VERSION ""

NS_ :

BS_:

BU_: GENERIC_SENSOR_HUB

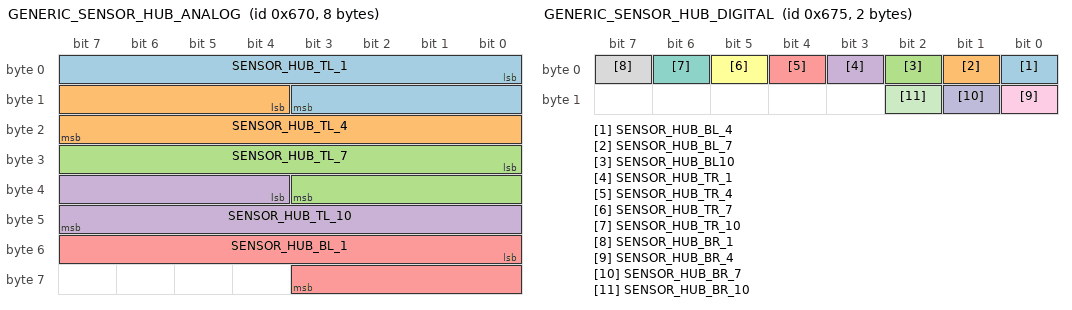
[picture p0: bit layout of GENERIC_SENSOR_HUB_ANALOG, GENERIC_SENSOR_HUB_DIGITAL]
BO_ 1648 GENERIC_SENSOR_HUB_ANALOG: 8 GENERIC_SENSOR_HUB
 SG_ SENSOR_HUB_TL_1 : 0|12@1+ (0.0008056640625,0) [0|3.3] "V" Vector__XXX
 SG_ SENSOR_HUB_TL_4 : 12|12@1+ (0.0008056640625,0) [0|3.3] "V" Vector__XXX
 SG_ SENSOR_HUB_TL_7 : 24|12@1+ (0.0008056640625,0) [0|3.3] "V" Vector__XXX
 SG_ SENSOR_HUB_TL_10 : 36|12@1+ (0.0008056640625,0) [0|3.3] "V" Vector__XXX
 SG_ SENSOR_HUB_BL_1 : 48|12@1+ (0.0008056640625,0) [0|3.3] "V" Vector__XXX

BO_ 1653 GENERIC_SENSOR_HUB_DIGITAL: 2 GENERIC_SENSOR_HUB
 SG_ SENSOR_HUB_BL_4 : 0|1@1+ (1,0) [0|1] "" Vector__XXX
 SG_ SENSOR_HUB_BL_7 : 1|1@1+ (1,0) [0|1] "" Vector__XXX
 SG_ SENSOR_HUB_BL10 : 2|1@1+ (1,0) [0|1] "" Vector__XXX
 SG_ SENSOR_HUB_TR_1 : 3|1@1+ (1,0) [0|1] "" Vector__XXX
 SG_ SENSOR_HUB_TR_4 : 4|1@1+ (1,0) [0|1] "" Vector__XXX
 SG_ SENSOR_HUB_TR_7 : 5|1@1+ (1,0) [0|1] "" Vector__XXX
 SG_ SENSOR_HUB_TR_10 : 6|1@1+ (1,0) [0|1] "" Vector__XXX
 SG_ SENSOR_HUB_BR_1 : 7|1@1+ (1,0) [0|1] "" Vector__XXX
 SG_ SENSOR_HUB_BR_4 : 8|1@1+ (1,0) [0|1] "" Vector__XXX
 SG_ SENSOR_HUB_BR_7 : 9|1@1+ (1,0) [0|1] "" Vector__XXX
 SG_ SENSOR_HUB_BR_10 : 10|1@1+ (1,0) [0|1] "" Vector__XXX

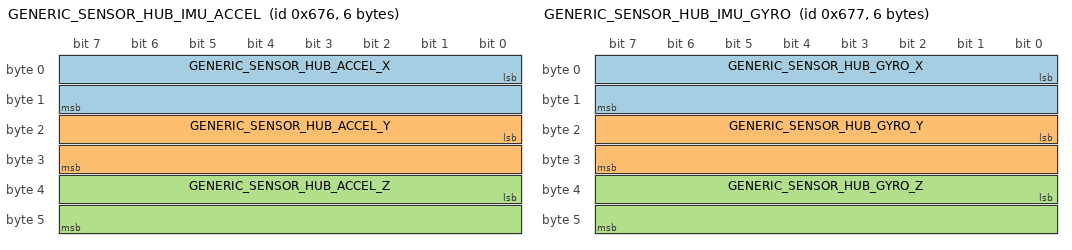
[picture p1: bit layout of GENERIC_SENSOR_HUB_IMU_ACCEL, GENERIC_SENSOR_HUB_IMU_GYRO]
BO_ 1654 GENERIC_SENSOR_HUB_IMU_ACCEL: 6 GENERIC_SENSOR_HUB
 SG_ GENERIC_SENSOR_HUB_ACCEL_X : 0|16@1- (0.000122,0) [-4|4] "g" Vector__XXX
 SG_ GENERIC_SENSOR_HUB_ACCEL_Y : 16|16@1- (0.000122,0) [-4|4] "g" Vector__XXX
 SG_ GENERIC_SENSOR_HUB_ACCEL_Z : 32|16@1- (0.000122,0) [-4|4] "g" Vector__XXX

BO_ 1655 GENERIC_SENSOR_HUB_IMU_GYRO: 6 GENERIC_SENSOR_HUB
 SG_ GENERIC_SENSOR_HUB_GYRO_X : 0|16@1- (0.0175,0) [-500|500] "dps" Vector__XXX
 SG_ GENERIC_SENSOR_HUB_GYRO_Y : 16|16@1- (0.0175,0) [-500|500] "dps" Vector__XXX
 SG_ GENERIC_SENSOR_HUB_GYRO_Z : 32|16@1- (0.0175,0) [-500|500] "dps" Vector__XXX

BO_ 1656 GENERIC_SENSOR_HUB_TEMP: 4 GENERIC_SENSOR_HUB
 SG_ GENERIC_SENSOR_HUB_IMU_TEMP : 0|16@1- (0.00390625,25) [-40|85] "degC" Vector__XXX
 SG_ GENERIC_SENSOR_HUB_AMBIENT_TEMP : 16|16@1- (0.0625,0) [-55|125] "degC" Vector__XXX

BO_ 1657 GENERIC_SENSOR_HUB_STATUS: 1 GENERIC_SENSOR_HUB
 SG_ GENERIC_SENSOR_HUB_ISM330_OK : 0|1@1+ (1,0) [0|1] "" Vector__XXX
 SG_ GENERIC_SENSOR_HUB_MCP9800_OK : 1|1@1+ (1,0) [0|1] "" Vector__XXX
